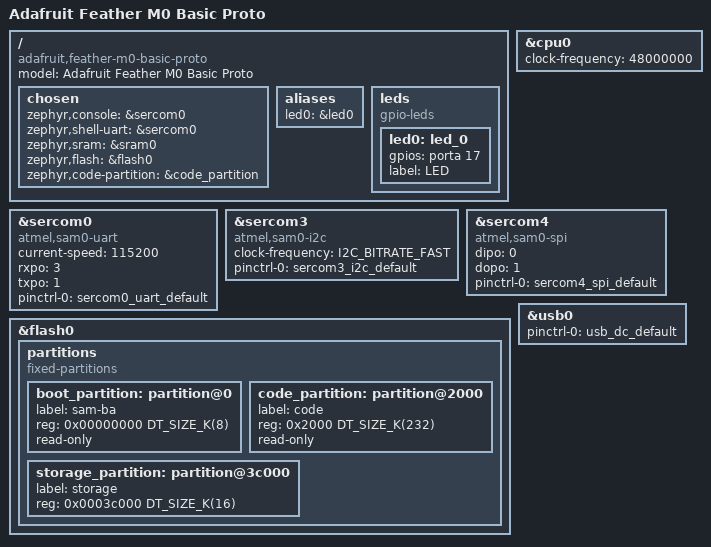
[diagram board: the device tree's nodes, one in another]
/*
 * Copyright (c) 2018 Henrik Brix Andersen <henrik@brixandersen.dk>
 *
 * SPDX-License-Identifier: Apache-2.0
 */

/dts-v1/;
#include <atmel/samd21.dtsi>
#include <atmel/samx2xx18.dtsi>
#include "adafruit_feather_m0_basic_proto-pinctrl.dtsi"
#include "feather_connector.dtsi"

/ {
	model = "Adafruit Feather M0 Basic Proto";
	compatible = "adafruit,feather-m0-basic-proto", "atmel,samd21g18a",
			"atmel,samd21";

	chosen {
		zephyr,console = &sercom0;
		zephyr,shell-uart = &sercom0;
		zephyr,sram = &sram0;
		zephyr,flash = &flash0;
		zephyr,code-partition = &code_partition;
	};

	/* These aliases are provided for compatibility with samples */
	aliases {
		led0 = &led0;
	};

	leds {
		compatible = "gpio-leds";
		led0: led_0 {
			gpios = <&porta 17 0>;
			label = "LED";
		};
	};
};

&cpu0 {
	clock-frequency = <48000000>;
};

&sercom0 {
	status = "okay";
	compatible = "atmel,sam0-uart";
	current-speed = <115200>;
	rxpo = <3>;
	txpo = <1>;

	pinctrl-0 = <&sercom0_uart_default>;
	pinctrl-names = "default";
};

&sercom3 {
	status = "okay";
	compatible = "atmel,sam0-i2c";
	clock-frequency = <I2C_BITRATE_FAST>;
	#address-cells = <1>;
	#size-cells = <0>;

	pinctrl-0 = <&sercom3_i2c_default>;
	pinctrl-names = "default";
};

&sercom4 {
	status = "okay";
	compatible = "atmel,sam0-spi";
	#address-cells = <1>;
	#size-cells = <0>;
	dipo = <0>;
	dopo = <1>;

	pinctrl-0 = <&sercom4_spi_default>;
	pinctrl-names = "default";
};

&flash0 {
	partitions {
		compatible = "fixed-partitions";
		#address-cells = <1>;
		#size-cells = <1>;

		boot_partition: partition@0 {
			label = "sam-ba";
			reg = <0x00000000 DT_SIZE_K(8)>;
			read-only;
		};

		code_partition: partition@2000 {
			label = "code";
			reg = <0x2000 DT_SIZE_K(232)>;
			read-only;
		};

		/*
		 * The final 16 KiB is reserved for the application.
		 * Storage partition will be used by FCB/LittleFS/NVS
		 * if enabled.
		 */
		storage_partition: partition@3c000 {
			label = "storage";
			reg = <0x0003c000 DT_SIZE_K(16)>;
		};
	};
};

zephyr_udc0: &usb0 {
	status = "okay";

	pinctrl-0 = <&usb_dc_default>;
	pinctrl-names = "default";
};
